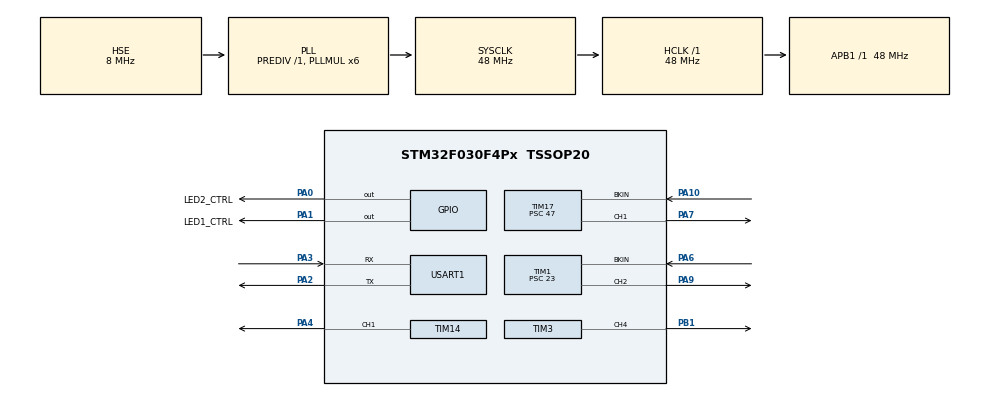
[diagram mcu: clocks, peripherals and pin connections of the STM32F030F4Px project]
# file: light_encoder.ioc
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Dma.Request0=USART1_RX
Dma.USART1_RX.0.Direction=DMA_PERIPH_TO_MEMORY
Dma.USART1_RX.0.Instance=DMA1_Channel3
Dma.USART1_RX.0.MemDataAlignment=DMA_MDATAALIGN_BYTE
Dma.USART1_RX.0.MemInc=DMA_MINC_ENABLE
Dma.USART1_RX.0.Mode=DMA_NORMAL
Dma.USART1_RX.0.PeriphDataAlignment=DMA_PDATAALIGN_BYTE
Dma.USART1_RX.0.PeriphInc=DMA_PINC_DISABLE
Dma.USART1_RX.0.Priority=DMA_PRIORITY_HIGH
Mcu.Family=STM32F0
Mcu.Name=STM32F030F4Px
Mcu.Package=TSSOP20
NVIC.DMA1_Channel2_3_IRQn=true\:0\:0\:false\:false\:true\:false\:true\:true
NVIC.TIM17_IRQn=true\:0\:0\:false\:false\:true\:true\:true\:true
PA0.GPIO_Label=LED2_CTRL
PA0.GPIO_PuPd=GPIO_PULLDOWN
PA0.GPIO_Speed=GPIO_SPEED_FREQ_HIGH
PA0.Signal=GPIO_Output
PA1.GPIO_Label=LED1_CTRL
PA1.GPIO_PuPd=GPIO_PULLDOWN
PA1.GPIO_Speed=GPIO_SPEED_FREQ_HIGH
PA1.Signal=GPIO_Output
PA10.Mode=Activate-Break-Input
PA10.Signal=TIM17_BKIN
PA13.Mode=Serial_Wire
PA13.Signal=SYS_SWDIO
PA14.Mode=Serial_Wire
PA14.Signal=SYS_SWCLK
PA2.Mode=Asynchronous
PA2.Signal=USART1_TX
PA3.Mode=Asynchronous
PA3.Signal=USART1_RX
PA4.Signal=S_TIM14_CH1
PA6.Mode=Activate-Break-Input
PA6.Signal=TIM1_BKIN
PA7.Signal=S_TIM17_CH1
PA9.Signal=S_TIM1_CH2
PB1.Signal=S_TIM3_CH4
PF0-OSC_IN.Mode=HSE-External-Oscillator
PF0-OSC_IN.Signal=RCC_OSC_IN
PF1-OSC_OUT.Mode=HSE-External-Oscillator
PF1-OSC_OUT.Signal=RCC_OSC_OUT
ProjectManager.HeapSize=0x200
ProjectManager.StackSize=0x400
ProjectManager.TargetToolchain=MDK-ARM V5.32
RCC.AHBFreq_Value=48000000
RCC.APB1Freq_Value=48000000
RCC.APB1TimFreq_Value=48000000
RCC.HCLKFreq_Value=48000000
RCC.PLLMUL=RCC_PLL_MUL6
RCC.PLLSourceVirtual=RCC_PLLSOURCE_HSE
RCC.SYSCLKFreq_VALUE=48000000
RCC.SYSCLKSource=RCC_SYSCLKSOURCE_PLLCLK
SH.S_TIM14_CH1.0=TIM14_CH1,PWM Generation1 CH1
SH.S_TIM17_CH1.0=TIM17_CH1,PWM Generation1 CH1
SH.S_TIM1_CH2.0=TIM1_CH2,PWM Generation2 CH2
SH.S_TIM3_CH4.0=TIM3_CH4,PWM Generation4 CH4
TIM1.AutomaticOutput=TIM_AUTOMATICOUTPUT_ENABLE
TIM1.BreakPolarity=TIM_BREAKPOLARITY_LOW
TIM1.BreakState=TIM_BREAK_DISABLE
TIM1.Channel-PWM\ Generation2\ CH2=TIM_CHANNEL_2
TIM1.OCFastMode_PWM-PWM\ Generation2\ CH2=TIM_OCFAST_DISABLE
TIM1.OCPolarity_2=TIM_OCPOLARITY_LOW
TIM1.Period=9999
TIM1.Prescaler=23
TIM1.Pulse-PWM\ Generation2\ CH2=4999
TIM14.Channel=TIM_CHANNEL_1
TIM14.OCPolarity_1=TIM_OCPOLARITY_LOW
TIM14.Period=9999
TIM14.Prescaler=11
TIM14.Pulse=4999
TIM16.Period=1999
TIM16.Prescaler=47
TIM17.AutomaticOutput=TIM_AUTOMATICOUTPUT_ENABLE
TIM17.BreakPolarity=TIM_BREAKPOLARITY_LOW
TIM17.BreakState=TIM_BREAK_DISABLE
TIM17.Channel=TIM_CHANNEL_1
TIM17.OCPolarity_1=TIM_OCPOLARITY_LOW
TIM17.Period=9999
TIM17.Prescaler=47
TIM17.Pulse=4999
TIM3.Channel-PWM\ Generation4\ CH4=TIM_CHANNEL_4
TIM3.OCPolarity_4=TIM_OCPOLARITY_LOW
TIM3.Period=9999
TIM3.Prescaler=15
TIM3.Pulse-PWM\ Generation4\ CH4=4999
USART1.VirtualMode-Asynchronous=VM_ASYNC
VP_CRC_VS_CRC.Mode=CRC_Activate
VP_TIM14_VS_ClockSourceINT.Mode=Enable_Timer
VP_TIM16_VS_ClockSourceINT.Mode=Enable_Timer
VP_TIM17_VS_ClockSourceINT.Mode=Enable_Timer
VP_TIM1_VS_ClockSourceINT.Mode=Internal
VP_TIM3_VS_ClockSourceINT.Mode=Internal
board=custom

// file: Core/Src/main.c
/* USER CODE BEGIN Header */
/**
  ******************************************************************************
  * @file           : main.c
  * @brief          : Main program body
  ******************************************************************************
  * @attention
  *
  * Copyright (c) 2025 STMicroelectronics.
  * All rights reserved.
  *
  * This software is licensed under terms that can be found in the LICENSE file
  * in the root directory of this software component.
  * If no LICENSE file comes with this software, it is provided AS-IS.
  *
  ******************************************************************************
  */
/* USER CODE END Header */
#include "main.h"

/* USER CODE BEGIN Includes */
#include "vlc_send.h"
/* USER CODE END Includes */

CRC_HandleTypeDef hcrc;

TIM_HandleTypeDef htim1;
TIM_HandleTypeDef htim3;
TIM_HandleTypeDef htim14;
TIM_HandleTypeDef htim16;
TIM_HandleTypeDef htim17;

UART_HandleTypeDef huart1;
DMA_HandleTypeDef hdma_usart1_rx;

/* USER CODE BEGIN PV */
uint8_t rx_buf;
/* USER CODE END PV */

void SystemClock_Config(void);
static void MX_GPIO_Init(void);
static void MX_DMA_Init(void);
static void MX_CRC_Init(void);
static void MX_TIM1_Init(void);
static void MX_TIM3_Init(void);
static void MX_TIM14_Init(void);
static void MX_TIM16_Init(void);
static void MX_TIM17_Init(void);
static void MX_USART1_UART_Init(void);

/* USER CODE BEGIN 0 */
void HAL_UART_RxCpltCallback(UART_HandleTypeDef *huart)
{
    if (huart->Instance == USART1)
    {
        // Handle the received data stored in rxBuffer
        // For example, you can process the data or restart the DMA reception
        HAL_UART_Receive_DMA(&huart1, &rx_buf, 1);
        // add_byte(rx_buf);
    }
}
/* USER CODE END 0 */

int main(void)
{

  /* MCU Configuration--------------------------------------------------------*/

  /* Reset of all peripherals, Initializes the Flash interface and the Systick. */
  HAL_Init();

  /* Configure the system clock */
  SystemClock_Config();

  /* Initialize all configured peripherals */
  MX_GPIO_Init();
  MX_DMA_Init();
  MX_CRC_Init();
  MX_TIM1_Init();
  MX_TIM3_Init();
  MX_TIM14_Init();
  MX_TIM16_Init();
  MX_TIM17_Init();
  MX_USART1_UART_Init();
  /* USER CODE BEGIN 2 */
  uint8_t counter = 0;
  /* USER CODE END 2 */

  /* Infinite loop */
  /* USER CODE BEGIN WHILE */
  while (1)
  {
    // add_byte(counter++);
    // HAL_Delay(500);
    /* USER CODE END WHILE */

    /* USER CODE BEGIN 3 */
    HAL_UART_Receive_DMA(&huart1, &rx_buf, 1);
  }
  /* USER CODE END 3 */
}

void SystemClock_Config(void)
{
  RCC_OscInitTypeDef RCC_OscInitStruct = {0};
  RCC_ClkInitTypeDef RCC_ClkInitStruct = {0};
  RCC_PeriphCLKInitTypeDef PeriphClkInit = {0};

  /** Initializes the RCC Oscillators according to the specified parameters
  * in the RCC_OscInitTypeDef structure.
  */
  RCC_OscInitStruct.OscillatorType = RCC_OSCILLATORTYPE_HSE;
  RCC_OscInitStruct.HSEState = RCC_HSE_ON;
  RCC_OscInitStruct.PLL.PLLState = RCC_PLL_ON;
  RCC_OscInitStruct.PLL.PLLSource = RCC_PLLSOURCE_HSE;
  RCC_OscInitStruct.PLL.PLLMUL = RCC_PLL_MUL6;
  RCC_OscInitStruct.PLL.PREDIV = RCC_PREDIV_DIV1;
  if (HAL_RCC_OscConfig(&RCC_OscInitStruct) != HAL_OK)
  {
    Error_Handler();
  }

  /** Initializes the CPU, AHB and APB buses clocks
  */
  RCC_ClkInitStruct.ClockType = RCC_CLOCKTYPE_HCLK|RCC_CLOCKTYPE_SYSCLK
                              |RCC_CLOCKTYPE_PCLK1;
  RCC_ClkInitStruct.SYSCLKSource = RCC_SYSCLKSOURCE_PLLCLK;
  RCC_ClkInitStruct.AHBCLKDivider = RCC_SYSCLK_DIV1;
  RCC_ClkInitStruct.APB1CLKDivider = RCC_HCLK_DIV1;

  if (HAL_RCC_ClockConfig(&RCC_ClkInitStruct, FLASH_LATENCY_1) != HAL_OK)
  {
    Error_Handler();
  }
  PeriphClkInit.PeriphClockSelection = RCC_PERIPHCLK_USART1;
  PeriphClkInit.Usart1ClockSelection = RCC_USART1CLKSOURCE_PCLK1;
  if (HAL_RCCEx_PeriphCLKConfig(&PeriphClkInit) != HAL_OK)
  {
    Error_Handler();
  }
}

static void MX_CRC_Init(void)
{

  hcrc.Instance = CRC;
  hcrc.Init.DefaultInitValueUse = DEFAULT_INIT_VALUE_ENABLE;
  hcrc.Init.InputDataInversionMode = CRC_INPUTDATA_INVERSION_NONE;
  hcrc.Init.OutputDataInversionMode = CRC_OUTPUTDATA_INVERSION_DISABLE;
  hcrc.InputDataFormat = CRC_INPUTDATA_FORMAT_BYTES;
  if (HAL_CRC_Init(&hcrc) != HAL_OK)
  {
    Error_Handler();
  }

}

static void MX_TIM1_Init(void)
{

  TIM_ClockConfigTypeDef sClockSourceConfig = {0};
  TIM_MasterConfigTypeDef sMasterConfig = {0};
  TIM_OC_InitTypeDef sConfigOC = {0};
  TIM_BreakDeadTimeConfigTypeDef sBreakDeadTimeConfig = {0};

  htim1.Instance = TIM1;
  htim1.Init.Prescaler = 23;
  htim1.Init.CounterMode = TIM_COUNTERMODE_UP;
  htim1.Init.Period = 9999;
  htim1.Init.ClockDivision = TIM_CLOCKDIVISION_DIV1;
  htim1.Init.RepetitionCounter = 0;
  htim1.Init.AutoReloadPreload = TIM_AUTORELOAD_PRELOAD_DISABLE;
  if (HAL_TIM_Base_Init(&htim1) != HAL_OK)
  {
    Error_Handler();
  }
  sClockSourceConfig.ClockSource = TIM_CLOCKSOURCE_INTERNAL;
  if (HAL_TIM_ConfigClockSource(&htim1, &sClockSourceConfig) != HAL_OK)
  {
    Error_Handler();
  }
  if (HAL_TIM_PWM_Init(&htim1) != HAL_OK)
  {
    Error_Handler();
  }
  sMasterConfig.MasterOutputTrigger = TIM_TRGO_RESET;
  sMasterConfig.MasterSlaveMode = TIM_MASTERSLAVEMODE_DISABLE;
  if (HAL_TIMEx_MasterConfigSynchronization(&htim1, &sMasterConfig) != HAL_OK)
  {
    Error_Handler();
  }
  sConfigOC.OCMode = TIM_OCMODE_PWM1;
  sConfigOC.Pulse = 4999;
  sConfigOC.OCPolarity = TIM_OCPOLARITY_LOW;
  sConfigOC.OCNPolarity = TIM_OCNPOLARITY_HIGH;
  sConfigOC.OCFastMode = TIM_OCFAST_DISABLE;
  sConfigOC.OCIdleState = TIM_OCIDLESTATE_RESET;
  sConfigOC.OCNIdleState = TIM_OCNIDLESTATE_RESET;
  if (HAL_TIM_PWM_ConfigChannel(&htim1, &sConfigOC, TIM_CHANNEL_2) != HAL_OK)
  {
    Error_Handler();
  }
  sBreakDeadTimeConfig.OffStateRunMode = TIM_OSSR_DISABLE;
  sBreakDeadTimeConfig.OffStateIDLEMode = TIM_OSSI_DISABLE;
  sBreakDeadTimeConfig.LockLevel = TIM_LOCKLEVEL_OFF;
  sBreakDeadTimeConfig.DeadTime = 0;
  sBreakDeadTimeConfig.BreakState = TIM_BREAK_DISABLE;
  sBreakDeadTimeConfig.BreakPolarity = TIM_BREAKPOLARITY_LOW;
  sBreakDeadTimeConfig.AutomaticOutput = TIM_AUTOMATICOUTPUT_ENABLE;
  if (HAL_TIMEx_ConfigBreakDeadTime(&htim1, &sBreakDeadTimeConfig) != HAL_OK)
  {
    Error_Handler();
  }
  /* USER CODE BEGIN TIM1_Init 2 */
  HAL_TIM_PWM_Start(&htim1,TIM_CHANNEL_2);
  /* USER CODE END TIM1_Init 2 */
  HAL_TIM_MspPostInit(&htim1);

}

static void MX_TIM3_Init(void)
{

  TIM_ClockConfigTypeDef sClockSourceConfig = {0};
  TIM_MasterConfigTypeDef sMasterConfig = {0};
  TIM_OC_InitTypeDef sConfigOC = {0};

  htim3.Instance = TIM3;
  htim3.Init.Prescaler = 15;
  htim3.Init.CounterMode = TIM_COUNTERMODE_UP;
  htim3.Init.Period = 9999;
  htim3.Init.ClockDivision = TIM_CLOCKDIVISION_DIV1;
  htim3.Init.AutoReloadPreload = TIM_AUTORELOAD_PRELOAD_DISABLE;
  if (HAL_TIM_Base_Init(&htim3) != HAL_OK)
  {
    Error_Handler();
  }
  sClockSourceConfig.ClockSource = TIM_CLOCKSOURCE_INTERNAL;
  if (HAL_TIM_ConfigClockSource(&htim3, &sClockSourceConfig) != HAL_OK)
  {
    Error_Handler();
  }
  if (HAL_TIM_PWM_Init(&htim3) != HAL_OK)
  {
    Error_Handler();
  }
  sMasterConfig.MasterOutputTrigger = TIM_TRGO_RESET;
  sMasterConfig.MasterSlaveMode = TIM_MASTERSLAVEMODE_DISABLE;
  if (HAL_TIMEx_MasterConfigSynchronization(&htim3, &sMasterConfig) != HAL_OK)
  {
    Error_Handler();
  }
  sConfigOC.OCMode = TIM_OCMODE_PWM1;
  sConfigOC.Pulse = 4999;
  sConfigOC.OCPolarity = TIM_OCPOLARITY_LOW;
  sConfigOC.OCFastMode = TIM_OCFAST_DISABLE;
  if (HAL_TIM_PWM_ConfigChannel(&htim3, &sConfigOC, TIM_CHANNEL_4) != HAL_OK)
  {
    Error_Handler();
  }
  /* USER CODE BEGIN TIM3_Init 2 */
  HAL_TIM_PWM_Start(&htim3,TIM_CHANNEL_4);
  /* USER CODE END TIM3_Init 2 */
  HAL_TIM_MspPostInit(&htim3);

}

static void MX_TIM14_Init(void)
{

  TIM_OC_InitTypeDef sConfigOC = {0};

  htim14.Instance = TIM14;
  htim14.Init.Prescaler = 11;
  htim14.Init.CounterMode = TIM_COUNTERMODE_UP;
  htim14.Init.Period = 9999;
  htim14.Init.ClockDivision = TIM_CLOCKDIVISION_DIV1;
  htim14.Init.AutoReloadPreload = TIM_AUTORELOAD_PRELOAD_DISABLE;
  if (HAL_TIM_Base_Init(&htim14) != HAL_OK)
  {
    Error_Handler();
  }
  if (HAL_TIM_PWM_Init(&htim14) != HAL_OK)
  {
    Error_Handler();
  }
  sConfigOC.OCMode = TIM_OCMODE_PWM1;
  sConfigOC.Pulse = 4999;
  sConfigOC.OCPolarity = TIM_OCPOLARITY_LOW;
  sConfigOC.OCFastMode = TIM_OCFAST_DISABLE;
  if (HAL_TIM_PWM_ConfigChannel(&htim14, &sConfigOC, TIM_CHANNEL_1) != HAL_OK)
  {
    Error_Handler();
  }
  /* USER CODE BEGIN TIM14_Init 2 */
  HAL_TIM_PWM_Start(&htim14,TIM_CHANNEL_1);
  /* USER CODE END TIM14_Init 2 */
  HAL_TIM_MspPostInit(&htim14);

}

static void MX_TIM16_Init(void)
{

  htim16.Instance = TIM16;
  htim16.Init.Prescaler = 47;
  htim16.Init.CounterMode = TIM_COUNTERMODE_UP;
  htim16.Init.Period = 1999;
  htim16.Init.ClockDivision = TIM_CLOCKDIVISION_DIV1;
  htim16.Init.RepetitionCounter = 0;
  htim16.Init.AutoReloadPreload = TIM_AUTORELOAD_PRELOAD_DISABLE;
  if (HAL_TIM_Base_Init(&htim16) != HAL_OK)
  {
    Error_Handler();
  }

}

static void MX_TIM17_Init(void)
{

  TIM_OC_InitTypeDef sConfigOC = {0};
  TIM_BreakDeadTimeConfigTypeDef sBreakDeadTimeConfig = {0};

  htim17.Instance = TIM17;
  htim17.Init.Prescaler = 47;
  htim17.Init.CounterMode = TIM_COUNTERMODE_UP;
  htim17.Init.Period = 9999;
  htim17.Init.ClockDivision = TIM_CLOCKDIVISION_DIV1;
  htim17.Init.RepetitionCounter = 0;
  htim17.Init.AutoReloadPreload = TIM_AUTORELOAD_PRELOAD_DISABLE;
  if (HAL_TIM_Base_Init(&htim17) != HAL_OK)
  {
    Error_Handler();
  }
  if (HAL_TIM_PWM_Init(&htim17) != HAL_OK)
  {
    Error_Handler();
  }
  sConfigOC.OCMode = TIM_OCMODE_PWM1;
  sConfigOC.Pulse = 4999;
  sConfigOC.OCPolarity = TIM_OCPOLARITY_LOW;
  sConfigOC.OCNPolarity = TIM_OCNPOLARITY_HIGH;
  sConfigOC.OCFastMode = TIM_OCFAST_DISABLE;
  sConfigOC.OCIdleState = TIM_OCIDLESTATE_RESET;
  sConfigOC.OCNIdleState = TIM_OCNIDLESTATE_RESET;
  if (HAL_TIM_PWM_ConfigChannel(&htim17, &sConfigOC, TIM_CHANNEL_1) != HAL_OK)
  {
    Error_Handler();
  }
  sBreakDeadTimeConfig.OffStateRunMode = TIM_OSSR_DISABLE;
  sBreakDeadTimeConfig.OffStateIDLEMode = TIM_OSSI_DISABLE;
  sBreakDeadTimeConfig.LockLevel = TIM_LOCKLEVEL_OFF;
  sBreakDeadTimeConfig.DeadTime = 0;
  sBreakDeadTimeConfig.BreakState = TIM_BREAK_DISABLE;
  sBreakDeadTimeConfig.BreakPolarity = TIM_BREAKPOLARITY_LOW;
  sBreakDeadTimeConfig.AutomaticOutput = TIM_AUTOMATICOUTPUT_ENABLE;
  if (HAL_TIMEx_ConfigBreakDeadTime(&htim17, &sBreakDeadTimeConfig) != HAL_OK)
  {
    Error_Handler();
  }
  /* USER CODE BEGIN TIM17_Init 2 */
  HAL_TIM_PWM_Start(&htim17,TIM_CHANNEL_1);
  HAL_TIM_Base_Start_IT(&htim17);
  /* USER CODE END TIM17_Init 2 */
  HAL_TIM_MspPostInit(&htim17);

}

static void MX_USART1_UART_Init(void)
{

  huart1.Instance = USART1;
  huart1.Init.BaudRate = 38400;
  huart1.Init.WordLength = UART_WORDLENGTH_8B;
  huart1.Init.StopBits = UART_STOPBITS_1;
  huart1.Init.Parity = UART_PARITY_NONE;
  huart1.Init.Mode = UART_MODE_TX_RX;
  huart1.Init.HwFlowCtl = UART_HWCONTROL_NONE;
  huart1.Init.OverSampling = UART_OVERSAMPLING_16;
  huart1.Init.OneBitSampling = UART_ONE_BIT_SAMPLE_DISABLE;
  huart1.AdvancedInit.AdvFeatureInit = UART_ADVFEATURE_NO_INIT;
  if (HAL_UART_Init(&huart1) != HAL_OK)
  {
    Error_Handler();
  }

}

static void MX_DMA_Init(void)
{

  /* DMA controller clock enable */
  __HAL_RCC_DMA1_CLK_ENABLE();

  /* DMA interrupt init */
  /* DMA1_Channel2_3_IRQn interrupt configuration */
  HAL_NVIC_SetPriority(DMA1_Channel2_3_IRQn, 0, 0);
  HAL_NVIC_EnableIRQ(DMA1_Channel2_3_IRQn);

}

static void MX_GPIO_Init(void)
{
  GPIO_InitTypeDef GPIO_InitStruct = {0};

  /* GPIO Ports Clock Enable */
  __HAL_RCC_GPIOF_CLK_ENABLE();
  __HAL_RCC_GPIOA_CLK_ENABLE();
  __HAL_RCC_GPIOB_CLK_ENABLE();

  /*Configure GPIO pin Output Level */
  HAL_GPIO_WritePin(GPIOA, LED2_CTRL_Pin|LED1_CTRL_Pin, GPIO_PIN_RESET);

  /*Configure GPIO pins : LED2_CTRL_Pin LED1_CTRL_Pin */
  GPIO_InitStruct.Pin = LED2_CTRL_Pin|LED1_CTRL_Pin;
  GPIO_InitStruct.Mode = GPIO_MODE_OUTPUT_PP;
  GPIO_InitStruct.Pull = GPIO_PULLDOWN;
  GPIO_InitStruct.Speed = GPIO_SPEED_FREQ_HIGH;
  HAL_GPIO_Init(GPIOA, &GPIO_InitStruct);

}

void Error_Handler(void)
{
  __disable_irq();
  while (1)
  {
  }
}
